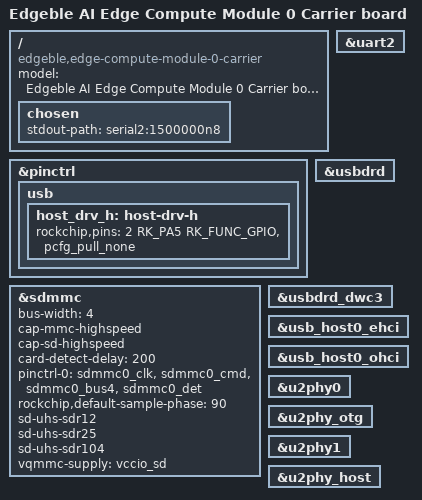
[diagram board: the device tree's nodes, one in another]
// SPDX-License-Identifier: (GPL-2.0+ OR MIT)
/*
 * Copyright (c) 2020 Rockchip Electronics Co., Ltd.
 * Copyright (c) 2022 Edgeble AI Technologies Pvt. Ltd.
 */

/dts-v1/;
#include "rv1126.dtsi"
#include "rv1126-edgeble-edge-compute-module-0.dtsi"

/ {
	model = "Edgeble AI Edge Compute Module 0 Carrier board";
	compatible = "edgeble,edge-compute-module-0-carrier",
		     "edgeble,edge-compute-module-0", "rockchip,rv1126";

	chosen {
		stdout-path = "serial2:1500000n8";
	};
};

&pinctrl {
	usb {
		host_drv_h: host-drv-h {
			rockchip,pins = <2 RK_PA5 RK_FUNC_GPIO &pcfg_pull_none>;
		};
	};
};

&sdmmc {
	bus-width = <4>;
	cap-mmc-highspeed;
	cap-sd-highspeed;
	card-detect-delay = <200>;
	pinctrl-names = "default";
	pinctrl-0 = <&sdmmc0_clk &sdmmc0_cmd &sdmmc0_bus4 &sdmmc0_det>;
	rockchip,default-sample-phase = <90>;
	sd-uhs-sdr12;
	sd-uhs-sdr25;
	sd-uhs-sdr104;
	vqmmc-supply = <&vccio_sd>;
	status = "okay";
};

&uart2 {
	status = "okay";
};

&usbdrd {
	status = "okay";
};

&usbdrd_dwc3 {
	status = "okay";
};

&usb_host0_ehci {
	status = "okay";
};

&usb_host0_ohci {
	status = "okay";
};

&u2phy0 {
	status = "okay";
};

&u2phy_otg {
	status = "okay";
};

&u2phy1 {
	status = "okay";
};

&u2phy_host {
	status = "okay";
};
